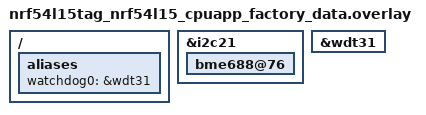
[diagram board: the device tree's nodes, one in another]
/*
 * Copyright (c) 2026 Nordic Semiconductor ASA
 *
 * SPDX-License-Identifier: LicenseRef-Nordic-5-Clause
 */

#include <samples/matter/nrf54lm20a_partitions.dtsi>

/ {
	aliases {
		/* Use watchdog wdt31 as the application watchdog */
		watchdog0 = &wdt31;
	};
};

/* BME688 (temperature pressure and humidity sensor) */
&i2c21 {
	bme688@76 {
		status = "okay";
	};
};

&wdt31 {
	status = "okay";
};
